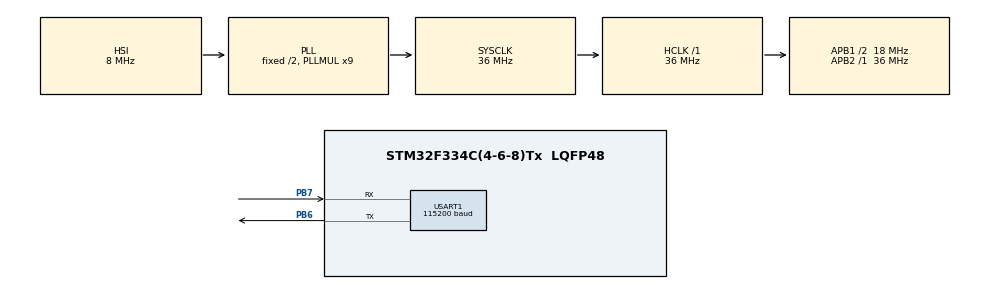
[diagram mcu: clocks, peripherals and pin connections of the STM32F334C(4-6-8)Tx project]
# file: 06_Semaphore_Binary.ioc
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FREERTOS.Tasks01=defaultTask,0,128,StartDefaultTask,Default,NULL,Dynamic,NULL,NULL
FREERTOS.configUSE_NEWLIB_REENTRANT=1
Mcu.Family=STM32F3
Mcu.Name=STM32F334C(4-6-8)Tx
Mcu.Package=LQFP48
NVIC.PriorityGroup=NVIC_PRIORITYGROUP_4
NVIC.TIM6_DAC1_IRQn=true\:15\:0\:false\:false\:true\:false\:false\:true\:true
NVIC.TimeBase=TIM6_DAC1_IRQn
NVIC.TimeBaseIP=TIM6
PA13.Mode=Serial_Wire
PA13.Signal=SYS_JTMS-SWDIO
PA14.Mode=Serial_Wire
PA14.Signal=SYS_JTCK-SWCLK
PB6.Mode=Asynchronous
PB6.Signal=USART1_TX
PB7.Mode=Asynchronous
PB7.Signal=USART1_RX
ProjectManager.HeapSize=0x200
ProjectManager.StackSize=0x400
ProjectManager.TargetToolchain=STM32CubeIDE
RCC.AHBFreq_Value=36000000
RCC.APB1CLKDivider=RCC_HCLK_DIV2
RCC.APB1Freq_Value=18000000
RCC.APB1TimFreq_Value=36000000
RCC.APB2Freq_Value=36000000
RCC.APB2TimFreq_Value=36000000
RCC.CortexFreq_Value=36000000
RCC.HCLKFreq_Value=36000000
RCC.HSE_VALUE=8000000
RCC.HSI_VALUE=8000000
RCC.LSE_VALUE=32768
RCC.PLLMUL=RCC_PLL_MUL9
RCC.SYSCLKFreq_VALUE=36000000
RCC.SYSCLKSourceVirtual=RCC_SYSCLKSOURCE_PLLCLK
USART1.BaudRate=115200
USART1.VirtualMode-Asynchronous=VM_ASYNC
VP_FREERTOS_VS_CMSIS_V1.Mode=CMSIS_V1
VP_SYS_VS_tim6.Mode=TIM6
board=STM32F3348-DISCO

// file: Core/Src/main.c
/* USER CODE BEGIN Header */
/**
  ******************************************************************************
  * @file           : main.c
  * @brief          : Main program body
  ******************************************************************************
  * @attention
  *
  * Copyright (c) 2023 STMicroelectronics.
  * All rights reserved.
  *
  * This software is licensed under terms that can be found in the LICENSE file
  * in the root directory of this software component.
  * If no LICENSE file comes with this software, it is provided AS-IS.
  *
  ******************************************************************************
  */
/* USER CODE END Header */
#include "main.h"

/* USER CODE BEGIN Includes */
#include "FreeRTOS.h"
#include "task.h"
#include "timers.h"
#include "queue.h"
#include "semphr.h"
#include "event_groups.h"
#include <stdlib.h>
#include <stdio.h>
#include <string.h>
/* USER CODE END Includes */

UART_HandleTypeDef huart1;

/* USER CODE BEGIN PV */
SemaphoreHandle_t xWorkSemaphore;

TaskHandle_t ManagerTask_Handle,EmployeeTask_Handle;
QueueHandle_t xWorkQueue;

/* USER CODE END PV */

void SystemClock_Config(void);
static void MX_GPIO_Init(void);
static void MX_USART1_UART_Init(void);

/* USER CODE BEGIN PFP */
static void vManagerTask_Handler(void *param);
static void vEmployeeTask_Handler(void *param);
void EmployeeDoWork(unsigned int ticket);

/* USER CODE END PFP */

int main(void)
{

  /* MCU Configuration--------------------------------------------------------*/

  /* Reset of all peripherals, Initializes the Flash interface and the Systick. */
  HAL_Init();

  /* Configure the system clock */
  SystemClock_Config();

  /* Initialize all configured peripherals */
  MX_GPIO_Init();
  MX_USART1_UART_Init();

  /* USER CODE BEGIN RTOS_SEMAPHORES */
  xWorkSemaphore = xSemaphoreCreateBinary();
  /* USER CODE END RTOS_SEMAPHORES */

  /* USER CODE BEGIN RTOS_QUEUES */
  xWorkQueue = xQueueCreate(1,sizeof(unsigned int));

  if((xWorkQueue != NULL) && (xWorkSemaphore != NULL))
  {
	  xTaskCreate(vManagerTask_Handler, "Manager", 128, NULL,3 ,&ManagerTask_Handle );
	  xTaskCreate(vEmployeeTask_Handler, "Employee", 128, NULL, 2, &EmployeeTask_Handle);
	  vTaskStartScheduler();
  }
  else
  {
	  while(1)
	  {
		  HAL_UART_Transmit(&huart1, (uint8_t*)"Either semaphore or queue is not created\r\n", sizeof("Either semaphore or queue is not created\r\n")-1, HAL_MAX_DELAY);
		  HAL_Delay(1000);
	  }
  }
  /* USER CODE END RTOS_QUEUES */

  /* Create the thread(s) */
  /* definition and creation of defaultTask */

  /* Start scheduler */

  /* We should never get here as control is now taken by the scheduler */
  /* Infinite loop */
  while (1)
  {

  }
}

void SystemClock_Config(void)
{
  RCC_OscInitTypeDef RCC_OscInitStruct = {0};
  RCC_ClkInitTypeDef RCC_ClkInitStruct = {0};
  RCC_PeriphCLKInitTypeDef PeriphClkInit = {0};

  /** Initializes the RCC Oscillators according to the specified parameters
  * in the RCC_OscInitTypeDef structure.
  */
  RCC_OscInitStruct.OscillatorType = RCC_OSCILLATORTYPE_HSI;
  RCC_OscInitStruct.HSIState = RCC_HSI_ON;
  RCC_OscInitStruct.HSICalibrationValue = RCC_HSICALIBRATION_DEFAULT;
  RCC_OscInitStruct.PLL.PLLState = RCC_PLL_ON;
  RCC_OscInitStruct.PLL.PLLSource = RCC_PLLSOURCE_HSI;
  RCC_OscInitStruct.PLL.PLLMUL = RCC_PLL_MUL9;
  if (HAL_RCC_OscConfig(&RCC_OscInitStruct) != HAL_OK)
  {
    Error_Handler();
  }

  /** Initializes the CPU, AHB and APB buses clocks
  */
  RCC_ClkInitStruct.ClockType = RCC_CLOCKTYPE_HCLK|RCC_CLOCKTYPE_SYSCLK
                              |RCC_CLOCKTYPE_PCLK1|RCC_CLOCKTYPE_PCLK2;
  RCC_ClkInitStruct.SYSCLKSource = RCC_SYSCLKSOURCE_PLLCLK;
  RCC_ClkInitStruct.AHBCLKDivider = RCC_SYSCLK_DIV1;
  RCC_ClkInitStruct.APB1CLKDivider = RCC_HCLK_DIV2;
  RCC_ClkInitStruct.APB2CLKDivider = RCC_HCLK_DIV1;

  if (HAL_RCC_ClockConfig(&RCC_ClkInitStruct, FLASH_LATENCY_1) != HAL_OK)
  {
    Error_Handler();
  }
  PeriphClkInit.PeriphClockSelection = RCC_PERIPHCLK_USART1;
  PeriphClkInit.Usart1ClockSelection = RCC_USART1CLKSOURCE_PCLK1;
  if (HAL_RCCEx_PeriphCLKConfig(&PeriphClkInit) != HAL_OK)
  {
    Error_Handler();
  }
}

static void MX_USART1_UART_Init(void)
{

  huart1.Instance = USART1;
  huart1.Init.BaudRate = 115200;
  huart1.Init.WordLength = UART_WORDLENGTH_8B;
  huart1.Init.StopBits = UART_STOPBITS_1;
  huart1.Init.Parity = UART_PARITY_NONE;
  huart1.Init.Mode = UART_MODE_TX_RX;
  huart1.Init.HwFlowCtl = UART_HWCONTROL_NONE;
  huart1.Init.OverSampling = UART_OVERSAMPLING_16;
  huart1.Init.OneBitSampling = UART_ONE_BIT_SAMPLE_DISABLE;
  huart1.AdvancedInit.AdvFeatureInit = UART_ADVFEATURE_NO_INIT;
  if (HAL_UART_Init(&huart1) != HAL_OK)
  {
    Error_Handler();
  }

}

static void MX_GPIO_Init(void)
{

  /* GPIO Ports Clock Enable */
  __HAL_RCC_GPIOA_CLK_ENABLE();
  __HAL_RCC_GPIOB_CLK_ENABLE();

}

/* USER CODE BEGIN 4 */
void vManagerTask_Handler(void *param)
{
	unsigned int xWorkTicketId;
	portBASE_TYPE xStatus;
	//initially make semaphore available
	 xSemaphoreGive(xWorkSemaphore);
	 while(1)
	 {
		 xWorkTicketId = (rand() & 0x1FF);

		 xStatus  = xQueueSend(xWorkQueue,&xWorkTicketId,portMAX_DELAY);
		 if(xStatus != pdPASS)
		 {
			 HAL_UART_Transmit(&huart1, (uint8_t*)"couldn't send to the queue\r\n", sizeof("couldn't send to the queue\r\n")-1, HAL_MAX_DELAY);
		 }
		 else
		 {
			 xSemaphoreGive(xWorkSemaphore);
			 taskYIELD();
		 }
	 }
}
static void vEmployeeTask_Handler(void *param)
{
	unsigned int xWorkTicketId;
		portBASE_TYPE xStatus;

		 while(1)
		 {
			 //portMAX_DELAY is timeout which makes the task wait
			 xSemaphoreTake(xWorkSemaphore,portMAX_DELAY);

			 xStatus  = xQueueReceive(xWorkQueue,&xWorkTicketId,0);

			 if(xStatus != pdPASS)
			 {
				 HAL_UART_Transmit(&huart1, (uint8_t*)"Employee: Queue is empty nothing to receive\r\n", sizeof("Employee: Queue is empty nothing to receive\r\n")-1, HAL_MAX_DELAY);
			 }
			 else
			 {
				 EmployeeDoWork(xWorkTicketId);
			 }
		 }
}
void EmployeeDoWork(unsigned int ticket)
{
	char msg[50];
	sprintf(msg,"Employee: Ticket Id %d\r\n",ticket);
	HAL_UART_Transmit(&huart1, (uint8_t*)msg, strlen(msg), HAL_MAX_DELAY);
}
/* USER CODE END 4 */

void HAL_TIM_PeriodElapsedCallback(TIM_HandleTypeDef *htim)
{
  if (htim->Instance == TIM6) {
    HAL_IncTick();
  }
}

void Error_Handler(void)
{
  __disable_irq();
  while (1)
  {
  }
}
